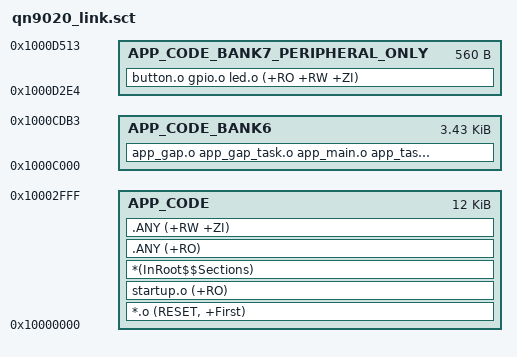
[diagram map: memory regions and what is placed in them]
; *************************************************************
; *** Scatter-Loading Description File generated by Quintic ***
; *************************************************************

LR_ROM1 0x10000000 0xF294
{
    APP_CODE 0x10000000 0x3000
    {
        *.o (RESET, +First)
        startup.o (+RO)
        *(InRoot$$Sections)
        .ANY (+RO)
        .ANY (+RW +ZI)
    }

    APP_CODE_BANK6 0x1000c000 0xDB4
    {
        app_gap.o app_gap_task.o app_main.o app_task.o app_util.o prf_utils.o sleep.o system.o (+RO +RW +ZI)
    }

    APP_CODE_BANK7_PERIPHERAL_ONLY 0x1000D2E4 0x230
    {
         button.o gpio.o led.o (+RO +RW +ZI)
    }
}

